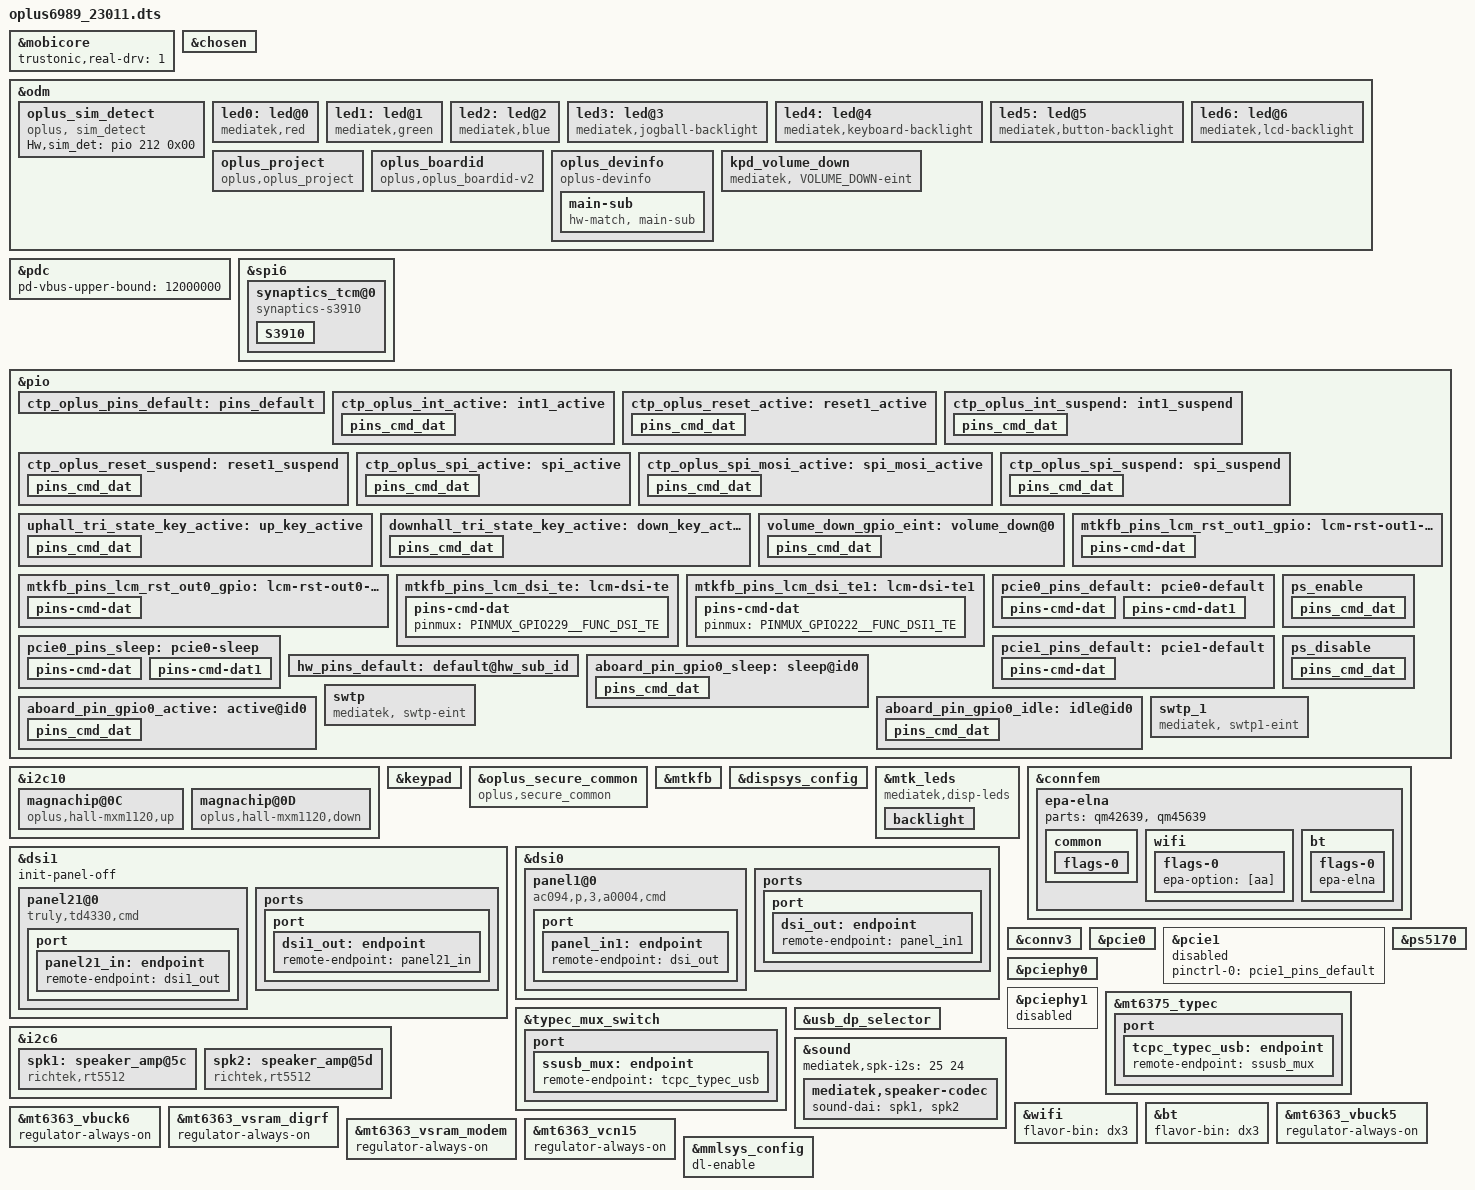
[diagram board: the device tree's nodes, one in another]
// SPDX-License-Identifier: (GPL-2.0 OR MIT)
/*
 * Copyright (C) 2022 MediaTek Inc.
 */
/dts-v1/;
/plugin/;
#include <dt-bindings/interrupt-controller/arm-gic.h>
#include <dt-bindings/interrupt-controller/irq.h>
#include <dt-bindings/pinctrl/mt6989-pinfunc.h>
#include <dt-bindings/phy/phy.h>
//#ifdef OPLUS_BUG_STABILITY
//NFC dtsi
#include "mediatek/nfc/mt6989_22113_sn220.dtsi"
//endif OPLUS_BUG_STABILITY

/* #ifdef OPLUS_FEATURE_CHG_BASIC */
/* Add for DX-3 charge device-tree */
#include "mediatek/oplus_misc_22113.dtsi"
/* #endif */

//#ifdef OPLUS_FEATURE_SENSOR
#include "mediatek/oplus_sensor_22113.dtsi"
//#endif

/* #ifdef OPLUS_FEATURE_CHG_BASIC */
#include "mediatek/oplus_charge_22113.dtsi"
/* #endif */

/* Trustonic Mobilecore real driver */
&mobicore{
        trustonic,real-drv = <1>;
};

/* Add for Egret(23011_23211) fingerprint device-tree */
/* #ifdef CONFIG_UFF_FINGERPRINT */
#include "mediatek/oplus_uff_23011_23211.dtsi"
/* #endif CONFIG_UFF_FINGERPRINT */

&chosen {
bootargs_ext = "kmemleak=off kasan=off \
loglevel=8 initcall_debug=1 \
log_buf_len=2m \
arm64.nopauth arm64.nosme arm64.nosve";
};

&odm {
/* Add for sim detect */
    oplus_sim_detect {
        compatible = "oplus, sim_detect";
        Hw,sim_det = <&pio 212 0x00>;
    };
};

/* #ifdef OPLUS_DISPLAY_FEATURE */
&odm {
	led0:led@0 {
		compatible = "mediatek,red";
		led_mode = <0>;
		data = <1>;
		pwm_config = <0 0 0 0 0>;
	};
	led1:led@1 {
		compatible = "mediatek,green";
		led_mode = <0>;
		data = <1>;
		pwm_config = <0 0 0 0 0>;
	};
	led2:led@2 {
		compatible = "mediatek,blue";
		led_mode = <0>;
		data = <1>;
		pwm_config = <0 0 0 0 0>;
	};
	led3:led@3 {
		compatible = "mediatek,jogball-backlight";
		led_mode = <0>;
		data = <1>;
		pwm_config = <0 0 0 0 0>;
	};
	led4:led@4 {
		compatible = "mediatek,keyboard-backlight";
		led_mode = <0>;
		data = <1>;
		pwm_config = <0 0 0 0 0>;
	};
	led5:led@5 {
		compatible = "mediatek,button-backlight";
		led_mode = <0>;
		data = <1>;
		pwm_config = <0 0 0 0 0>;
	};
	led6:led@6 {
		compatible = "mediatek,lcd-backlight";
		led_mode = <4>;
		data = <1>;
		pwm_config = <0 1 0 0 0>;
	};
};

&pdc {
	pd-vbus-upper-bound = <12000000>;
};


&spi6 {
	status = "okay";
	#address-cells = <1>;
	#size-cells = <0>;

	synaptics_tcm@0{
		compatible = "synaptics-s3910";
		reg = <0x0>;
		chip-name = "S3910";
		status = "okay";
		spi-max-frequency = <19000000>;
		/* Interrupt && Irq-gpio */
		interrupt-parent = <&pio>;
		interrupts = <6 0x2008>;

		/* Power Config */
		/* enable2v8_gpio  = <&pio 164 0x1>; */
		vdd_2v8-supply = <&mt6373_vtp>;
		vdd_2v8_volt = <3000000>;
		/* vcc_1v8-supply  = <&mt6373_vmc>; */
		/* vcc_1v8_volt = <1800000>; */

		/* Other HW Resource */

		irq-gpio = <&pio 6 0x2008>;
		reset-gpio = <&pio 3 0x1>;
		//cs-gpio = <&pio 110 0x00>;

		pinctrl-names = "default",  "oplus_int_active",
		"oplus_reset_active", "oplus_int_suspend",
		"oplus_reset_suspend", "oplus_spi_active",
		"oplus_spi_suspend";
		pinctrl-0 = <&ctp_oplus_pins_default>;
		pinctrl-1 = <&ctp_oplus_int_active>;
		pinctrl-2 = <&ctp_oplus_reset_active>;
		pinctrl-3 = <&ctp_oplus_int_suspend>;
		pinctrl-4 = <&ctp_oplus_reset_suspend>;
		pinctrl-5 = <&ctp_oplus_spi_active>, <&ctp_oplus_spi_mosi_active>;
		pinctrl-6 = <&ctp_oplus_spi_suspend>;

		touchpanel,max-num-support = <10>;
		touchpanel,tx-rx-num = <18 39>;
		touchpanel,panel-coords = <12640 27800>;
		touchpanel,display-coords = <1264 2780>;
		touchpanel,touchmajor-limit = <128 216>;
		touchpanel,elimination-range = <20 200 200>;
		touchpanel,int-mode = <1>; /*0: interrupt and disable, 1:interrupt and not disable*/
		touchpanel,smooth-level = <0 1 2 4 7 9>;
		touchpanel,smooth-level-charging = <0 2 4 7 8 9>;
		touchpanel,sensitive-level = <0 70 55 40 25 10>;
		touchpanel,single-optimized-time = <8>;
		touchpanel,high-frame-rate-time = <60>;

		vid_len = <2>;
		panel_type = <7 7>; /*type:7 TIANMA*/
		platform_support_project = <22113>;
		platform_support_project_dir = <22113>;
		platform_support_project_commandline = "panel_ac094_p_3_a0004_dsi_cmd_lcm_drv", "oplus21121_boe_nt37701a_fhd_dsi_cmd_lcm_drv";

		prevention,curved_screen_V2;
		prevention,grip_disable_level = <6>;
		prevention,updelay_time_ms = <30>;
		prevention,makeup_cnt_weight = <4 1 2 2 2>;
		prevention,large_corner_range = <1380 3400>;
		prevention,large_corner_judge_condition = <500 300 1000 7 7>;
		prevention,trx_reject_condition = <8 7 7>;
		prevention,trx_strict_reject_condition = <8 6 6>;
		prevention,large_judge_time_ms = <500 50 30>;
		prevention,large_exit_condition = <8 8 2>;
		prevention,single_channel_width = <320 320>;
		prevention,normal_tap_condition = <10 350>;
		prevention,long_edge_condition = <179 90 120 80>;
		prevention,long_strict_edge_condition = <160 60>;
		prevention,long_fingerhold_condition = <70 6 4 4>;
		prevention,short_edge_condition = <179 90 120 80>;
		prevention,short_strict_edge_condition = <160 60>;
		prevention,large_strict_exit_condition = <6 6>;
		prevention,top_corner_config = <250 750 1000>;
		prevention,edge_swipe_config = <340 1130>;

		prevention,curved_screen_V4;
		prevention,long_eliminate_point_type = <2 12400 9240 240 27720 300 1>;
		prevention,long_fingerhold_condition2 = <700 2000 0 0>;
		prevention,top_corner_config2 =<3 80 600 1500 0>;
		prevention,hor_long_top_corner_config =<300 2000 0 0>;
		prevention,top_middle_config =<12400 1000 1000 0>;
		prevention,corner_eliminate_point_type =<0 1380 2270 1>;
		prevention,finger_hold_differ_size = <1 0 400 300>;
		prevention,finger_hold_max_rx_exit_distance = <5 350 2300>;
		prevention,max_rx_exit_distance = <1 5 150 350 2000>;
		prevention,dynamic_finger_hold_exit_distance = <1 350 2300 450>;
		prevention,edge_sliding_matched_support = <1 150 3 0>;

		/* SW Support Feature Control */
		black_gesture_support;
		sportify_aod_gesture_support;
		pressure_report_support;
		charger_pump_support;
		game_switch_support;
		glove_mode_support;
		smart_gesture_support;
		spi_port_support;
		fw_update_app_support;
		fingerprint_underscreen_support;
		freq_hop_simulate_support;
		report_flow_unlock_support;
		screenoff_fingerprint_info_support;
		irq_need_dev_resume_ok;
		enable_point_auto_change;
		kernel_grip_support;
		//grip_no_driver_support;
		health_monitor_support;
		black_gesture_indep_support;
		snr_read_support;
		palm_to_sleep_support;
		exception_upload_support;
		tp_data_record_support;
		fingerprint_not_report_in_suspend;
		/*
		 *Virtual Key Config:
		 *1:touchpanel,button-type: <virtualkey_type  supportted_button-map>
		 *virtualkey_type:
		 *Type 1: using board_properties
		 *Type 2: using same IC (button zone&& touch zone are seprate)
		 *Type 3: using diffrent IC (button zone&& touch zone are seprate)
		 *Type 4: No need of virtual key process
		 *supportted_button-map:select|menu|home|back
		 *
		 *2:touchpanel,button-map
		 *type (X1,Y1)(X2,Y2)(X3,Y3)(Width_X,Hight_Y)--Only when button-type is 0
		 */
		touchpanel,button-type = <4>;
		touchpanel.button-TRx = <0 0>;

		S3910 {
			switch_report_rate;
			report_rate_default = <60>;
			report_rate_game_value = <0x03>;
			fps_report_rate = <60 2 90 3 120 3>;//1:360Hz 2:125Hz 3:240Hz
			fwupdate_bootloader = <1>;
			normal_config_version = <2>;
			default_gesture_mask = <8191>;
		};
	};

};

/*add for nvwa TP*/
&pio {
	ctp_oplus_pins_default: pins_default {
	};
	ctp_oplus_int_active: int1_active {
		pins_cmd_dat {
			pinmux = <PINMUX_GPIO6__FUNC_GPIO6>;
			bias-disable;
			input-enable;
		};
	};
	ctp_oplus_reset_active: reset1_active {
		pins_cmd_dat {
			pinmux = <PINMUX_GPIO3__FUNC_GPIO3>;
			output-high;
		};
	};
	ctp_oplus_int_suspend: int1_suspend {
		pins_cmd_dat {
			pinmux = <PINMUX_GPIO6__FUNC_GPIO6>;
			output-low;
		};
	};
	ctp_oplus_reset_suspend: reset1_suspend {
		pins_cmd_dat {
			pinmux = <PINMUX_GPIO3__FUNC_GPIO3>;
			output-low;
		};
	};
	ctp_oplus_spi_active: spi_active {
		pins_cmd_dat {
			pinmux = <PINMUX_GPIO232__FUNC_SPI6_B_CSB>,
				<PINMUX_GPIO233__FUNC_SPI6_B_MO>,
				<PINMUX_GPIO231__FUNC_SPI6_B_CLK>;
			bias-disable;
			drive-strength = <4>;
		};
	};
	ctp_oplus_spi_mosi_active: spi_mosi_active {
		pins_cmd_dat {
			pinmux = <PINMUX_GPIO234__FUNC_SPI6_B_MI>;
			bias-pull-up;
			drive-strength = <4>;
		};
	};
	ctp_oplus_spi_suspend: spi_suspend {
		pins_cmd_dat {
			pinmux = < PINMUX_GPIO234__FUNC_GPIO234>,
				< PINMUX_GPIO232__FUNC_GPIO232>,
				<PINMUX_GPIO233__FUNC_GPIO233>,
				< PINMUX_GPIO231__FUNC_GPIO231>;
			bias-disable;
			output-low;
			drive-strength = <4>;
		};
	};
};

&i2c10 {
	status = "ok";
	/delete-node/ magnachip@0D;
	/delete-node/ magnachip@0C;
	/delete-node/ ist8801@19;
	/delete-node/ ist8801@18;

	magnachip@0C {
		compatible = "oplus,hall-mxm1120,up";
		reg = <0x0C>;
		vdd-supply = <&mt6373_vio28>;
		vdd_volt = <3000000>;
		vio-supply = <&mt6363_vio18>;
		vio_volt = <1800000>;
		magnachip,init-interval = <200>;
		interrups = <210 0x02>;
		dhall,irq-gpio = <&pio 210 0x2008>;
		pinctrl-names = "uphall_tri_state_key_active";
		pinctrl-0 = <&uphall_tri_state_key_active>;
	};

	magnachip@0D {
		compatible = "oplus,hall-mxm1120,down";
		reg = <0x0D>;
		vdd-supply = <&mt6373_vio28>;
		vdd_volt = <3000000>;
		vio-supply = <&mt6363_vio18>;
		vio_volt = <1800000>;
		magnachip,init-interval = <200>;
		interrups = <211 0x02>;
		dhall,irq-gpio = <&pio 211 0x2008>;
		pinctrl-names = "downhall_tri_state_key_active";
		pinctrl-0 = <&downhall_tri_state_key_active>;
	};
};

/*add for nvwa tri_state_key*/
&pio {
	/* 227 228  210*/
	uphall_tri_state_key_active: up_key_active {
		pins_cmd_dat {
			pinmux = <PINMUX_GPIO210__FUNC_GPIO210>;
			bias-pull-up;
			input-enable;
		};
	};
	downhall_tri_state_key_active: down_key_active {
		pins_cmd_dat {
			pinmux = <PINMUX_GPIO211__FUNC_GPIO211>;
			bias-pull-up;
			input-enable;
		};
	};
};


&keypad {
        keypad,volume-down = <&pio 11 0x00>;
        pinctrl-names = "volume_down_as_int";
        pinctrl-0 = <&volume_down_gpio_eint>;
        status = "okay";
};

&pio {
        volume_down_gpio_eint:volume_down@0{
                pins_cmd_dat {
                        pinmux = <PINMUX_GPIO11__FUNC_GPIO11>;
                        slew-rate = <0>;  /*direction 0:in, 1:out*/
                        input-enable;
                        bias-disable;
                };
        };
};

&oplus_secure_common {
    compatible = "oplus,secure_common";
    oplus,sec_reg_num = <0>;
    oplus,sec_en_anti_reg = <0>;
    oplus,sec_override1_reg = <0>;
    oplus,override1_en_value = <0>;
};

&pio {
	mtkfb_pins_lcm_rst_out1_gpio: lcm-rst-out1-gpio {
		pins-cmd-dat {
			pinmux = <PINMUX_GPIO230__FUNC_GPIO230>;
			slew-rate = <1>;
			output-high;
		};
	};

	mtkfb_pins_lcm_rst_out0_gpio: lcm-rst-out0-gpio {
		pins-cmd-dat {
			pinmux = <PINMUX_GPIO230__FUNC_GPIO230>;
			slew-rate = <1>;
			output-low;
		};
	};
	mtkfb_pins_lcm_dsi_te: lcm-dsi-te {
		pins-cmd-dat {
			pinmux = <PINMUX_GPIO229__FUNC_DSI_TE>;
		};
	};

	mtkfb_pins_lcm_dsi_te1: lcm-dsi-te1 {
		pins-cmd-dat {
			pinmux = <PINMUX_GPIO222__FUNC_DSI1_TE>;
		};
	};

};

&mtkfb {
	pinctrl-names = "lcm_rst_out1_gpio", "lcm_rst_out0_gpio",
		"mode_te_te", "mode_te_te1";
	pinctrl-0 = <&mtkfb_pins_lcm_rst_out1_gpio>;
	pinctrl-1 = <&mtkfb_pins_lcm_rst_out0_gpio>;
	pinctrl-2 = <&mtkfb_pins_lcm_dsi_te>;
	pinctrl-3 = <&mtkfb_pins_lcm_dsi_te1>;

	status = "okay";
};

&dispsys_config {
	pinctrl-names = "mode_te_te", "mode_te_te1";
	pinctrl-0 = <&mtkfb_pins_lcm_dsi_te>;
	pinctrl-1 = <&mtkfb_pins_lcm_dsi_te1>;
	status = "okay";
	lcm_id2 = <0>;
};

/*  OPLUS_DISPLAY_FEATURE */
&mtk_leds {
	compatible = "mediatek,disp-leds";
	status = "okay";

	backlight {
		label = "lcd-backlight";
		led_mode = <4>;
		min-brightness = <1>;
		max-brightness = <4095>;
		max-hw-brightness = <4095>;
		led-bits = <13>;
		trans-bits = <13>;
		default-state = "on";
	};
};
/*  OPLUS_DISPLAY_FEATURE */

&dsi1 {
//	status = "okay";
	#address-cells = <1>;
	#size-cells = <0>;
	init-panel-off;
	panel21@0 {
		compatible = "truly,td4330,cmd";
		reg = <1>;
		pm-enable-gpios = <&pio 215 0>;
		reset-gpios = <&pio 230 0>;
		gate-ic = <4831>;
		pinctrl-names = "default";
		port {
			panel21_in: endpoint {
				remote-endpoint = <&dsi1_out>;
			};
		};
	};
	ports {
		port {
			dsi1_out: endpoint {
				remote-endpoint = <&panel21_in>;
			};
		};
	};
};

&dsi0 {
	status = "okay";
	#address-cells = <1>;
	#size-cells = <0>;
	/** #ifdef OPLUS_DISPLAY_FEATURE **/
	panel1@0 {
		compatible = "ac094,p,3,a0004,cmd";
		reg = <0>;
		pm-enable-gpios = <&pio 86 0>;
		reset-gpios = <&pio 230 0>;
		1p8-supply = <&mt6373_vrfio18_aif>;
		3p0-supply = <&mt6373_vmc>;
		oplus,dsi-serial-number-enabled=<1>;
		oplus,dsi-serial-number-switch-page;
		oplus,dsi-serial-number-index= <0>;
		oplus,dsi-serial-number-switch-page-command= <0xFF 0x08 0x38 0x1D>;
		oplus,dsi-serial-number-default-switch-page-command= <0xFF 0x08 0x38 0x00>;
		oplus,dsi-serial-number-reg= <0x82>;
		oplus,dsi-serial-number-read-count= <7>;
		/* 0 not support, 1 with switch, 2 Global high frequency pwm without switch */
		// oplus,pwm-turbo-support = <2>;
		// oplus,pwm-switch-backlight-threshold = <0x4c7>;
		oplus-adfr-config = <0x1>;
		/* ofp config */
		oplus,ofp-fp-type = <0x10>;
		oplus,ofp-fp-type-compatible-mode;
		oplus,ofp-need-to-update-lhbm-pressed-icon-gamma;
		oplus,ofp-lhbm-dbv-alpha-cmd-index = <1>;
		oplus,ofp-lhbm-dbv-alpha-register-offset = <1>;
		oplus,ofp-lhbm-dbv-alpha-value = <
			/* lhbm dbv alpha value from 0 to 1087 */
			0x0CC 0x0CC 0x0CC 0x0CC 0x0CC 0x0CC 0x0CC 0x0CC 0x0CC 0x0CC 0x0CC 0x0CC 0x0CC 0x0CC 0x0CC 0x0CC 0x0CC 0x0CC 0x0CC 0x0CC
			0x0CC 0x0CC 0x0CC 0x0CC 0x0CC 0x0CC 0x0CC 0x0CC 0x0CC 0x0CC 0x0CC 0x0CC 0x0CC 0x0CC 0x0CC 0x0CC 0x0CC 0x0CC 0x0CC 0x0CC
			0x0CC 0x0CD 0x0CD 0x0CE 0x0CE 0x0CF 0x0D0 0x0D0 0x0D0 0x0D1 0x0D0 0x0D1 0x0D2 0x0D2 0x0D2 0x0D3 0x0D3 0x0D4 0x0D4 0x0D4
			0x0D4 0x0D5 0x0D5 0x0D5 0x0D6 0x0D6 0x0D6 0x0D6 0x0D7 0x0D7 0x0D7 0x0D8 0x0D9 0x0D9 0x0D9 0x0DA 0x0DA 0x0DA 0x0DB 0x0DB
			0x0DC 0x0DC 0x0DD 0x0DD 0x0DE 0x0DE 0x0DE 0x0DE 0x0DF 0x0DF 0x0E0 0x0E0 0x0E1 0x0E1 0x0E2 0x0E2 0x0E3 0x0E3 0x0E3 0x0E4
			0x0E4 0x0E5 0x0E5 0x0E5 0x0E6 0x0E6 0x0E6 0x0E7 0x0E7 0x0E8 0x0E8 0x0E9 0x0E9 0x0E9 0x0EA 0x0EA 0x0EA 0x0EB 0x0EB 0x0EC
			0x0EC 0x0ED 0x0ED 0x0EE 0x0EE 0x0EF 0x0EF 0x0EF 0x0F0 0x0F0 0x0F1 0x0F2 0x0F1 0x0F2 0x0F3 0x0F3 0x0F4 0x0F4 0x0F5 0x0F5
			0x0F6 0x0F6 0x0F7 0x0F7 0x0F8 0x0F8 0x0F8 0x0F9 0x0F9 0x0FA 0x0FA 0x0FB 0x0FC 0x0FC 0x0FC 0x0FD 0x0FD 0x0FD 0x0FD 0x0FF
			0x0FF 0x100 0x101 0x101 0x101 0x102 0x102 0x102 0x102 0x104 0x104 0x104 0x105 0x105 0x106 0x107 0x108 0x108 0x107 0x109
			0x109 0x109 0x10A 0x10B 0x10B 0x10C 0x10C 0x10C 0x10E 0x10E 0x10E 0x10F 0x110 0x110 0x111 0x111 0x111 0x111 0x112 0x113
			0x114 0x115 0x115 0x115 0x116 0x116 0x117 0x116 0x118 0x119 0x119 0x119 0x11A 0x11A 0x11B 0x11C 0x11D 0x11B 0x11E 0x11E
			0x11E 0x11F 0x11F 0x120 0x120 0x121 0x122 0x122 0x123 0x124 0x124 0x125 0x125 0x126 0x126 0x127 0x126 0x128 0x129 0x129
			0x12A 0x12A 0x12B 0x12C 0x12C 0x12D 0x12C 0x12E 0x12F 0x12F 0x130 0x130 0x131 0x132 0x132 0x133 0x132 0x134 0x134 0x134
			0x135 0x135 0x136 0x137 0x137 0x137 0x137 0x13A 0x13A 0x13B 0x13C 0x13C 0x13C 0x13D 0x13D 0x13D 0x13F 0x140 0x140 0x141
			0x143 0x143 0x143 0x144 0x144 0x144 0x146 0x147 0x147 0x148 0x149 0x149 0x149 0x14B 0x14C 0x14B 0x14C 0x14D 0x14E 0x14F
			0x150 0x150 0x151 0x151 0x152 0x151 0x154 0x155 0x155 0x156 0x157 0x157 0x158 0x159 0x159 0x158 0x15B 0x15B 0x15B 0x15C
			0x15E 0x15F 0x15E 0x160 0x15F 0x161 0x161 0x163 0x163 0x164 0x164 0x166 0x166 0x168 0x168 0x169 0x16A 0x16A 0x16B 0x16B
			0x16C 0x16D 0x16E 0x16E 0x16E 0x16F 0x171 0x172 0x173 0x173 0x174 0x174 0x175 0x175 0x176 0x178 0x178 0x179 0x179 0x17B
			0x17C 0x17D 0x17D 0x17E 0x17E 0x180 0x181 0x181 0x181 0x182 0x183 0x184 0x184 0x185 0x187 0x189 0x189 0x18A 0x18A 0x18B
			0x18C 0x18D 0x18D 0x18D 0x18E 0x190 0x191 0x193 0x193 0x194 0x194 0x195 0x196 0x196 0x198 0x198 0x199 0x199 0x19A 0x19D
			0x19D 0x19D 0x19F 0x19F 0x1A0 0x1A1 0x1A1 0x1A2 0x1A3 0x1A4 0x1A4 0x1A5 0x1A6 0x1A7 0x1A9 0x1A9 0x1A9 0x1AA 0x1AD 0x1AD
			0x1AE 0x1AD 0x1AF 0x1B0 0x1B0 0x1B0 0x1B2 0x1B2 0x1B2 0x1B3 0x1B6 0x1B6 0x1B7 0x1B7 0x1B8 0x1B9 0x1B9 0x1B8 0x1BA 0x1BC
			0x1BC 0x1BD 0x1BE 0x1BF 0x1BF 0x1C0 0x1C2 0x1C2 0x1C3 0x1C2 0x1C5 0x1C6 0x1C6 0x1C5 0x1C8 0x1CA 0x1CA 0x1CA 0x1CB 0x1CB
			0x1CC 0x1CD 0x1CF 0x1CF 0x1CF 0x1CF 0x1D1 0x1D2 0x1D3 0x1D3 0x1D5 0x1D6 0x1D6 0x1D7 0x1D7 0x1D8 0x1D9 0x1DA 0x1DA 0x1DB
			0x1DC 0x1DD 0x1DD 0x1E0 0x1E1 0x1E0 0x1E1 0x1E3 0x1E4 0x1E4 0x1E3 0x1E6 0x1E6 0x1E8 0x1E8 0x1E9 0x1E9 0x1EA 0x1EA 0x1ED
			0x1ED 0x1EE 0x1ED 0x1F0 0x1F1 0x1F2 0x1F2 0x1F3 0x1F4 0x1F5 0x1F6 0x1F6 0x1F7 0x1F7 0x1F9 0x1FB 0x1FB 0x1FC 0x1FB 0x1FE
			0x1FF 0x200 0x1FF 0x201 0x201 0x203 0x203 0x205 0x206 0x206 0x207 0x208 0x209 0x209 0x209 0x20A 0x20C 0x20D 0x20D 0x20D
			0x20F 0x211 0x211 0x212 0x213 0x214 0x214 0x215 0x216 0x217 0x218 0x219 0x21A 0x21B 0x21B 0x21B 0x21E 0x21E 0x21F 0x21F
			0x222 0x221 0x223 0x224 0x225 0x225 0x225 0x226 0x229 0x229 0x229 0x229 0x22B 0x22D 0x22E 0x22D 0x22E 0x22F 0x231 0x232
			0x234 0x235 0x235 0x236 0x238 0x238 0x239 0x239 0x23A 0x23C 0x23C 0x23B 0x23E 0x23F 0x241 0x242 0x240 0x243 0x244 0x246
			0x246 0x246 0x247 0x249 0x249 0x24A 0x24B 0x24C 0x24C 0x24F 0x250 0x251 0x250 0x252 0x253 0x255 0x254 0x256 0x257 0x258
			0x258 0x25B 0x25B 0x25B 0x25B 0x25D 0x25E 0x25F 0x25F 0x261 0x261 0x263 0x264 0x265 0x266 0x266 0x266 0x268 0x26A 0x26A
			0x26B 0x26D 0x26F 0x26F 0x270 0x271 0x272 0x272 0x272 0x274 0x276 0x277 0x277 0x279 0x27A 0x27A 0x27B 0x27C 0x27D 0x27F
			0x27E 0x280 0x281 0x281 0x283 0x283 0x285 0x285 0x285 0x287 0x289 0x289 0x289 0x28B 0x28C 0x28C 0x28D 0x28D 0x28E 0x28F
			0x290 0x291 0x292 0x293 0x295 0x294 0x295 0x297 0x296 0x298 0x29A 0x29A 0x29B 0x29B 0x29D 0x29E 0x29F 0x29F 0x2A0 0x2A1
			0x2A2 0x2A2 0x2A4 0x2A4 0x2A6 0x2A7 0x2A7 0x2A8 0x2A8 0x2A9 0x2AA 0x2AC 0x2AC 0x2AC 0x2AF 0x2B0 0x2B0 0x2B1 0x2B2 0x2B2
			0x2B4 0x2B5 0x2B6 0x2B7 0x2B8 0x2B8 0x2B8 0x2B9 0x2BA 0x2BC 0x2BC 0x2BD 0x2BE 0x2C0 0x2BF 0x2C2 0x2C1 0x2C3 0x2C4 0x2C4
			0x2C6 0x2C7 0x2C7 0x2C7 0x2C7 0x2CA 0x2CB 0x2CC 0x2CC 0x2CD 0x2CE 0x2CF 0x2D0 0x2D0 0x2D0 0x2D3 0x2D4 0x2D3 0x2D5 0x2D7
			0x2D7 0x2D9 0x2DA 0x2D8 0x2DB 0x2DC 0x2DC 0x2DD 0x2DF 0x2E0 0x2E1 0x2E1 0x2E2 0x2E2 0x2E3 0x2E4 0x2E6 0x2E6 0x2E7 0x2E9
			0x2EA 0x2EA 0x2EB 0x2EC 0x2EE 0x2EE 0x2EF 0x2EE 0x2F1 0x2F1 0x2F2 0x2F4 0x2F4 0x2F5 0x2F6 0x2F7 0x2F8 0x2F9 0x2FA 0x2FB
			0x2FD 0x2FD 0x2FC 0x2FF 0x300 0x2FF 0x2FF 0x2FF 0x2FF 0x303 0x305 0x306 0x307 0x308 0x309 0x308 0x308 0x30C 0x30C 0x30C
			0x30E 0x30F 0x310 0x311 0x312 0x312 0x313 0x313 0x314 0x315 0x317 0x318 0x318 0x318 0x319 0x31B 0x31C 0x31D 0x31E 0x31E
			0x320 0x321 0x321 0x320 0x324 0x325 0x326 0x327 0x327 0x329 0x32A 0x32B 0x32A 0x32C 0x32E 0x32E 0x32D 0x32F 0x331 0x331
			0x333 0x334 0x334 0x334 0x335 0x337 0x338 0x338 0x339 0x33A 0x33B 0x33B 0x33C 0x33C 0x33D 0x33E 0x341 0x342 0x343 0x343
			0x345 0x345 0x346 0x347 0x348 0x34B 0x349 0x34B 0x34C 0x34D 0x34F 0x34E 0x351 0x350 0x350 0x354 0x354 0x354 0x356 0x357
			0x358 0x358 0x359 0x359 0x359 0x35A 0x35D 0x35E 0x35F 0x360 0x360 0x360 0x361 0x362 0x364 0x366 0x366 0x367 0x368 0x369
			0x36A 0x36B 0x36C 0x36D 0x36E 0x36F 0x370 0x371 0x371 0x371 0x372 0x375 0x376 0x377 0x378 0x379 0x37B 0x37B 0x37C 0x37D
			0x37D 0x37F 0x37F 0x380 0x381 0x382 0x382 0x385 0x385 0x386 0x387 0x388 0x388 0x389 0x38A 0x38B 0x38D 0x38E 0x38E 0x38F
			0x391 0x391 0x392 0x393 0x394 0x395 0x395 0x396 0x397 0x398 0x39A 0x39B 0x39C 0x39D 0x39D 0x39E 0x3A0 0x3A0 0x3A0 0x3A2
			0x3A3 0x3A3 0x3A4 0x3A5 0x3A6 0x3A7 0x3A7 0x3A8 0x3AA 0x3AB 0x3AB 0x3AE 0x3AE 0x3AE 0x3B0 0x3B0 0x3B0 0x3B1 0x3B3 0x3B4
			0x3B5 0x3B6 0x3B6 0x3B8 0x3B8 0x3B9 0x3BB 0x3BC 0x3BC 0x3BE 0x3BE 0x3C0 0x3C0 0x3C1 0x3C2 0x3C3 0x3C3 0x3C5 0x3C6 0x3C6
			0x3C8 0x3C8 0x3C9 0x3CA 0x3CB 0x3CB 0x3CD 0x3CE 0x3CE 0x3D0 0x3D0 0x3D2 0x3D3 0x3D3 0x3D4 0x3D5 0x3D6 0x3D6 0x3D8 0x3D9
			0x3D9 0x3DB 0x3DC 0x3DD 0x3DE 0x3DE 0x3DF 0x3E0 0x3E1 0x3E2 0x3E3 0x3E4 0x3E5 0x3E6 0x3E7 0x3E8 0x3E9 0x3E9 0x3EB 0x3EC
			0x3EC 0x3EE 0x3EE 0x3EF 0x3F1 0x3F1 0x3F2 0x3F3 0x3F4 0x3F4 0x3F7 0x3F7 0x3F8 0x3F9 0x3FA 0x3FA 0x3FB 0x3FB 0x3FC 0x3FE
			0x3FF 0x400 0x400 0x400 0x400 0x400 0x400 0x400
		>;
		res-switch = <2>;
		pinctrl-names = "default";
		port {
			panel_in1: endpoint {
				remote-endpoint = <&dsi_out>;
			};
		};
	};
	/** #endif OPLUS_DISPLAY_FEATURE **/
	ports {
		port {
			dsi_out: endpoint {
				remote-endpoint = <&panel_in1>;
			};
		};
	};
};

&connfem {
	/* Support Wifi & BT ePA/eLNA FEM on customer load */
	epa-elna {
		parts = <&qm42639 &qm45639>;

		common {
			flags-0 {
				rx-mode = [35];
				fe-ant-cnt = [82];
				fe-main-bt-share-lp2g = [80];
				fe-conn-spdt = [8B];
				fe-reserved = [80];
			};
		};

		wifi {
			flags-0 {
				epa-option = [aa];
				/* open-loop; */
			};
		};

		bt {
			flags-0 {
				/* choose one of: epa-elna/epa/elna/bypass */
				epa-elna;
			};
		};
	};
};

/* #ifdef OPLUS_FEATURE_WIFI_SWITCH */
&connv3 {
	pinctrl-names = "connsys-pin-pmic-en-default",
					"connsys-pin-pmic-en-set",
					"connsys-pin-pmic-en-clr",
					"connsys-pin-pmic-faultb-default",
					"connsys-pin-pmic-faultb-enable",
					"connsys-combo-gpio-init",
					"connsys-combo-gpio-pre-on",
					"connsys-combo-gpio-on";
	pinctrl-0 = <&connsys_pin_pmic_en_default>;
	pinctrl-1 = <&connsys_pin_pmic_en_set>;
	pinctrl-2 = <&connsys_pin_pmic_en_clr>;
	pinctrl-3 = <&connsys_pin_pmic_faultb_default>;
	pinctrl-4 = <&connsys_pin_pmic_faultb_enable>;
	pinctrl-5 = <&connsys_combo_gpio_init>;
	pinctrl-6 = <&connsys_combo_gpio_pre_on>;
	pinctrl-7 = <&connsys_combo_gpio_on>;

	/delete-property/ pinctrl-8;
	/delete-property/ pinctrl-9;
};

&pio {
	/delete-node/ connsys_pin_pmic_vsel_low;
	/delete-node/ connsys_pin_pmic_vsel_high;
};
// #endif /* OPLUS_FEATURE_WIFI_SWITCH */

&pcie0 {
	pinctrl-names = "default", "sleep";
	pinctrl-0 = <&pcie0_pins_default>;
	pinctrl-1 = <&pcie0_pins_sleep>;
	max-link-speed = <3>;
	status = "okay";
};

&pcie1 {
	pinctrl-names = "default";
	pinctrl-0 = <&pcie1_pins_default>;
	status = "disabled";
};

&pciephy0 {
	status = "okay";
};

&pciephy1 {
	status = "disabled";
};

/* PCIe pinmux start */
&pio {
	pcie0_pins_default: pcie0-default {
		pins-cmd-dat {
			pinmux = <PINMUX_GPIO143__FUNC_PCIE_PERSTN>,
				 <PINMUX_GPIO145__FUNC_PCIE_CLKREQN>;
			bias-pull-up;
		};

		pins-cmd-dat1 {
			pinmux = <PINMUX_GPIO144__FUNC_GPIO144>;
			bias-pull-down;
			input-enable;
		};
	};

	pcie0_pins_sleep: pcie0-sleep {
		pins-cmd-dat {
			pinmux = <PINMUX_GPIO143__FUNC_GPIO143>;
			bias-pull-down;
			input-enable;
		};

		pins-cmd-dat1 {
			pinmux = <PINMUX_GPIO144__FUNC_GPIO144>,
				 <PINMUX_GPIO145__FUNC_GPIO145>;
			bias-pull-up;
			input-enable;
		};
	};

	pcie1_pins_default: pcie1-default {
		pins-cmd-dat {
			pinmux = <PINMUX_GPIO2__FUNC_PCIE_CLKREQN_P1>,
				 <PINMUX_GPIO4__FUNC_PCIE_PERSTN_P1>;
			bias-pull-up;
		};
	};
};
/* PCIe pinmux end */

#if 0
/* GPS GPIO standardization start */
&pio {
	gps_pins_default: gps_default {
	};
	gps_l1_lna_pins_ol: gps-l1-lna0 {
		pins-cmd-dat {
			pinmux = <PINMUX_GPIO12__FUNC_GPIO12>;
			output-low;
		};
	};
	gps_l1_lna_pins_dsp_ctrl: gps-l1-lna1 {
		pins-cmd-dat {
			pinmux = <PINMUX_GPIO12__FUNC_GPS_L1_ELNA_EN>;
		};
	};
	gps_l1_lna_pins_oh: gps-l1-lna2 {
		pins-cmd-dat {
			pinmux = <PINMUX_GPIO12__FUNC_GPIO12>;
			output-high;
		};
	};
	gps_l5_lna_pins_ol: gps-l5-lna0 {
		pins-cmd-dat {
			pinmux = <PINMUX_GPIO13__FUNC_GPIO13>;
			output-low;
		};
	};
	gps_l5_lna_pins_dsp_ctrl: gps-l5-lna1 {
		pins-cmd-dat {
			pinmux = <PINMUX_GPIO13__FUNC_GPS_L5_ELNA_EN>;
		};
	};
	gps_l5_lna_pins_oh: gps-l5-lna2 {
		pins-cmd-dat {
			pinmux = <PINMUX_GPIO13__FUNC_GPIO13>;
			output-high;
		};
	};
};
&gps {
	pinctrl-names = "default",
		"gps_l1_lna_disable",
		"gps_l1_lna_dsp_ctrl",
		"gps_l1_lna_enable",
		"gps_l5_lna_disable",
		"gps_l5_lna_dsp_ctrl",
		"gps_l5_lna_enable";
	pinctrl-0 = <&gps_pins_default>;
	pinctrl-1 = <&gps_l1_lna_pins_ol>;
	pinctrl-2 = <&gps_l1_lna_pins_dsp_ctrl>;
	pinctrl-3 = <&gps_l1_lna_pins_oh>;
	pinctrl-4 = <&gps_l5_lna_pins_ol>;
	pinctrl-5 = <&gps_l5_lna_pins_dsp_ctrl>;
	pinctrl-6 = <&gps_l5_lna_pins_oh>;
	status = "okay";
};
/* GPS GPIO standardization end */
#endif

/* usb typec mux start */
&pio {

	ps_enable: ps_enable {
		pins_cmd_dat {
//			pinmux = <PINMUX_GPIO111__FUNC_GPIO111>;
//			output-high;
		};
	};

	ps_disable: ps_disable {
		pins_cmd_dat {
//			pinmux = <PINMUX_GPIO111__FUNC_GPIO111>;
//			output-low;
		};
	};

};

&mt6375_typec {
	port {
		tcpc_typec_usb: endpoint {
			remote-endpoint = <&ssusb_mux>;
		};
	};
};

&typec_mux_switch {
	orientation-switch;
	mode-switch;
	accessory;
	port {
		ssusb_mux: endpoint {
			remote-endpoint = <&tcpc_typec_usb>;
		};
	};
};

&ps5170 {
	pinctrl-names = "enable", "disable";
	pinctrl-0 = <&ps_enable>;
	pinctrl-1 = <&ps_disable>;
	status = "okay";
};

&usb_dp_selector {
	status = "okay";
};
/* usb typec mux end */

#if 0
&pdc {
	pd_vbus_upper_bound = <12000000>;
};
#endif

&i2c6 {
	spk1: speaker_amp@5c {
		compatible = "richtek,rt5512";
		#sound-dai-cells = <0>;
		reg = <0x5c>;
		status = "okay";
		sound-name-prefix = "Left";
	};

	spk2: speaker_amp@5d {
		compatible = "richtek,rt5512";
		#sound-dai-cells = <0>;
		reg = <0x5d>;
		status = "okay";
		sound-name-prefix = "Right";
	};
};

&sound {
	mediatek,spk-i2s = <25 24>;
	mediatek,speaker-codec {
		sound-dai = <&spk1>, <&spk2>;
	};
};

&odm {
/*OPLUS_FEATURE_OEM_OCDT oppo project start */
	oplus_project:oplus_project {
		compatible = "oplus,oplus_project";
	};

    oplus_boardid:oplus_boardid {
		compatible = "oplus,oplus_boardid-v2";
		support-dtsino=<23011>;//only one u32
		/*first one is low 32bit, last one is highest 32bit, must be 32-bit for 4gpios*/
		support-pcbmask=<0xffffffff 0xffffffff 0xffffffff>;
	};

        oplus_devinfo:oplus_devinfo {
		compatible = "oplus-devinfo";
		pinctrl-names = "default", "aboard_gpio0_sleep", "aboard_gpio0_active", "aboard_gpio0_idle";
		pinctrl-0 = <&hw_pins_default>;
		pinctrl-1 = <&aboard_pin_gpio0_sleep>;
		pinctrl-2 = <&aboard_pin_gpio0_active>;
		pinctrl-3 = <&aboard_pin_gpio0_idle>;
		main-sub {
			use_tristate_gpio;
			compatible = "hw-match, main-sub";
			aboard-gpio0 = <&pio 126 0x00>;
			aboard-patterns = <0 1>;        /*0[high-resistance] 1[pull-down] 2[pull-up]*/
			/*main board*/
			match-projects = <22113 22113>;
		};
	};

	kpd_volume_down:kpd_volume_down {
		compatible = "mediatek, VOLUME_DOWN-eint";
		interrupt-parent = <&pio>;
		interrupts = <11 IRQ_TYPE_EDGE_FALLING 11 0>;
		debounce = <32000>;
		status = "okay";
	};
};
&pio{
        hw_pins_default:default@hw_sub_id {
	};

        aboard_pin_gpio0_sleep:sleep@id0 {
		pins_cmd_dat {
			pinmux = <PINMUX_GPIO126__FUNC_GPIO126>;
			slew-rate = <0>;
			bias-pull-down;
			input-enable;
		};
	};

	aboard_pin_gpio0_active:active@id0 {
		pins_cmd_dat {
			pinmux = <PINMUX_GPIO126__FUNC_GPIO126>;
			slew-rate = <0>;
			bias-pull-up;
			input-enable;
		};
	};

	aboard_pin_gpio0_idle:idle@id0 {
		pins_cmd_dat {
			pinmux = <PINMUX_GPIO126__FUNC_GPIO126>;
			slew-rate = <0>;
			bias-disable;
			input-enable;
		};
	};

    //#ifdef OPLUS_VENDOR_SWTP
    swtp: swtp {
        compatible = "mediatek, swtp-eint";
    };
    swtp_1: swtp_1 {
        compatible = "mediatek, swtp1-eint";
    };
    //#endif  /*OPLUS_VENDOR_SWTP*/

};

&wifi {
	flavor-bin = "dx3";
};

&bt {
	flavor-bin = "dx3";
};

&mt6363_vbuck5 {
	regulator-always-on;
};

&mt6363_vbuck6 {
	regulator-always-on;
};

&mt6363_vsram_digrf {
	regulator-always-on;
};

&mt6363_vsram_modem {
	regulator-always-on;
};

&mt6363_vcn15 {
	regulator-always-on;
};

&mmlsys_config {
	dl-enable;
};

#include <oplus6989_23011/cust.dtsi>
#include "mediatek/cust_k6989_connfem.dtsi"
#include "mediatek/cust_mt6989_touch_1080x2400.dtsi"
#include "mediatek/cust_mt6989_nvwa_camera_v4l2.dtsi"
#include "mediatek/cust_mt6989_22113_audio.dtsi"
#include "mediatek/cust_mt6989_nvwa_thermal.dtsi"
/*End of this file, DO NOT ADD ANYTHING HERE*/
